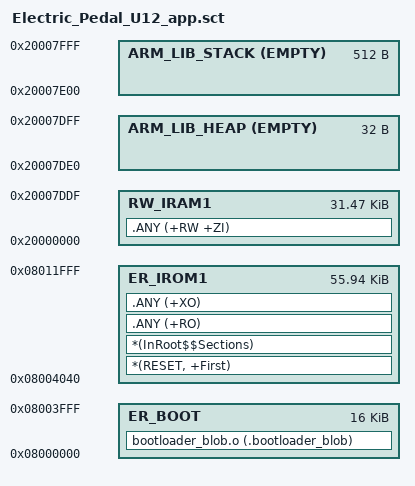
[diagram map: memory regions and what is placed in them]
LR_BOOT 0x08000000 0x00004000  {
  ER_BOOT 0x08000000 0x00004000  {
    bootloader_blob.o (.bootloader_blob)
  }
}

LR_APP 0x08004040 0x0000DFC0  {
  ER_IROM1 0x08004040 0x0000DFC0  {
    *(RESET, +First)
    *(InRoot$$Sections)
    .ANY (+RO)
    .ANY (+XO)
  }
  RW_IRAM1 0x20000000 0x00007DE0  {
    .ANY (+RW +ZI)
  }
  ARM_LIB_HEAP 0x20007DE0 EMPTY 0x00000020  { }
  ARM_LIB_STACK 0x20008000 EMPTY -0x00000200 { }
}
